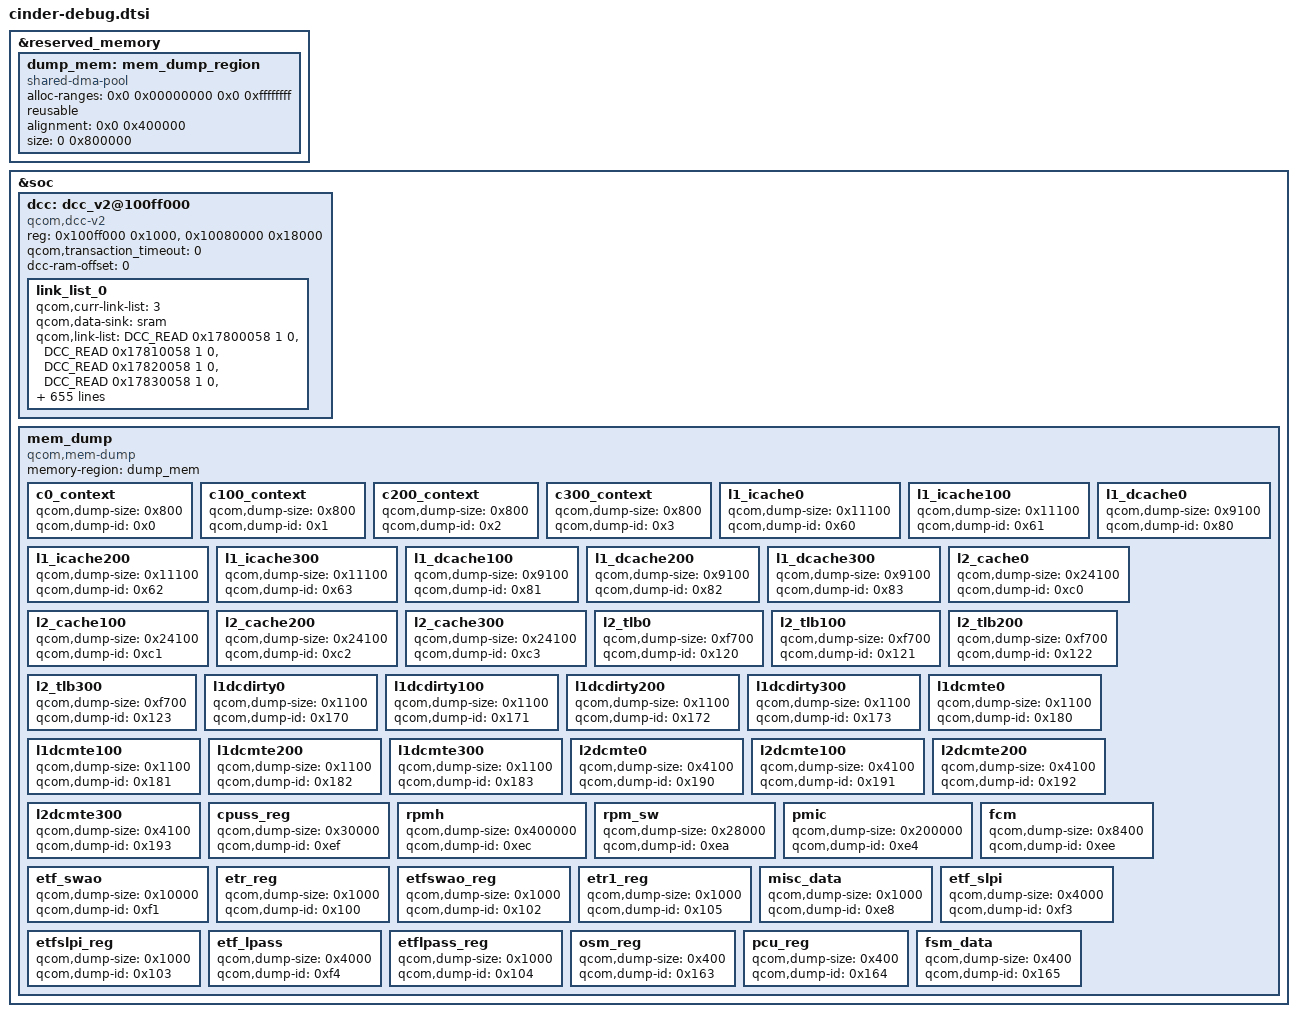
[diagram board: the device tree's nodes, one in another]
#include <dt-bindings/soc/qcom,dcc_v2.h>

&reserved_memory {
	#address-cells = <2>;
	#size-cells = <2>;
	ranges;

	dump_mem: mem_dump_region {
		compatible = "shared-dma-pool";
		alloc-ranges = <0x0 0x00000000 0x0 0xffffffff>;
		reusable;
		alignment = <0x0 0x400000>;
		size = <0 0x800000>;
	};
};

&soc {
	dcc: dcc_v2@100ff000 {
		compatible = "qcom,dcc-v2";
		reg = <0x100ff000 0x1000>,
		      <0x10080000 0x18000>;

		qcom,transaction_timeout = <0>;
		reg-names = "dcc-base", "dcc-ram-base";
		dcc-ram-offset = <0>;
		link_list_0 {
			qcom,curr-link-list = <3>;
			qcom,data-sink = "sram";
			qcom,link-list = <DCC_READ 0x17800058 1 0>,
					<DCC_READ 0x17810058 1 0>,
					<DCC_READ 0x17820058 1 0>,
					<DCC_READ 0x17830058 1 0>,
					<DCC_READ 0x1780005c 1 0>,
					<DCC_READ 0x1781005c 1 0>,
					<DCC_READ 0x1782005c 1 0>,
					<DCC_READ 0x1783005c 1 0>,
					<DCC_READ 0x1740003c 1 0>,
					<DCC_READ 0x17800060 1 0>,
					<DCC_READ 0x17810060 1 0>,
					<DCC_READ 0x17820060 1 0>,
					<DCC_READ 0x17830060 1 0>,
					<DCC_READ 0x17800064 1 0>,
					<DCC_READ 0x17810064 1 0>,
					<DCC_READ 0x17820064 1 0>,
					<DCC_READ 0x17830064 1 0>,
					<DCC_READ 0x17600238 1 0>,
					<DCC_READ 0x17600404 1 0>,
					<DCC_READ 0x1760041c 2 0>,
					<DCC_READ 0x17600434 1 0>,
					<DCC_READ 0x1760043c 2 0>,
					<DCC_WRITE 0x17a80000 0x8007 0>,
					<DCC_READ 0x17a80000 1 0>,
					<DCC_WRITE 0x17a80024 0x0 0>,
					<DCC_READ 0x17a80024 1 0>,
					<DCC_WRITE 0x17a80020 0x0 0>,
					<DCC_READ 0x17a80020 1 0>,
					<DCC_READ 0x17a80038 1 0>,
					<DCC_WRITE 0x17a80020 0x40 0>,
					<DCC_READ 0x17a80020 1 0>,
					<DCC_READ 0x17a80038 1 0>,
					<DCC_WRITE 0x17a80020 0x80 0>,
					<DCC_READ 0x17a80020 1 0>,
					<DCC_READ 0x17a80038 1 0>,
					<DCC_WRITE 0x17a80020 0xc0 0>,
					<DCC_READ 0x17a80020 1 0>,
					<DCC_READ 0x17a80038 1 0>,
					<DCC_WRITE 0x17a80020 0x100 0>,
					<DCC_READ 0x17a80020 1 0>,
					<DCC_READ 0x17a80038 1 0>,
					<DCC_WRITE 0x17a80020 0x140 0>,
					<DCC_READ 0x17a80020 1 0>,
					<DCC_READ 0x17a80038 1 0>,
					<DCC_WRITE 0x17a80020 0x180 0>,
					<DCC_READ 0x17a80020 1 0>,
					<DCC_READ 0x17a80038 1 0>,
					<DCC_WRITE 0x17a80020 0x1c0 0>,
					<DCC_READ 0x17a80020 1 0>,
					<DCC_READ 0x17a80038 1 0>,
					<DCC_WRITE 0x17a80020 0x200 0>,
					<DCC_READ 0x17a80020 1 0>,
					<DCC_READ 0x17a80038 1 0>,
					<DCC_WRITE 0x17a80020 0x240 0>,
					<DCC_READ 0x17a80020 1 0>,
					<DCC_READ 0x17a80038 1 0>,
					<DCC_WRITE 0x17a80020 0x280 0>,
					<DCC_READ 0x17a80020 1 0>,
					<DCC_READ 0x17a80038 1 0>,
					<DCC_WRITE 0x17a80020 0x2c0 0>,
					<DCC_READ 0x17a80020 1 0>,
					<DCC_READ 0x17a80038 1 0>,
					<DCC_WRITE 0x17a80020 0x300 0>,
					<DCC_READ 0x17a80020 1 0>,
					<DCC_READ 0x17a80038 1 0>,
					<DCC_WRITE 0x17a80020 0x340 0>,
					<DCC_READ 0x17a80020 1 0>,
					<DCC_READ 0x17a80038 1 0>,
					<DCC_WRITE 0x17a80020 0x380 0>,
					<DCC_READ 0x17a80020 1 0>,
					<DCC_READ 0x17a80038 1 0>,
					<DCC_WRITE 0x17a80020 0x3c0 0>,
					<DCC_READ 0x17a80020 1 0>,
					<DCC_READ 0x17a80038 1 0>,
					<DCC_WRITE 0x17a80020 0x4000 0>,
					<DCC_READ 0x17a80020 1 0>,
					<DCC_WRITE 0x17a80020 0x0 0>,
					<DCC_READ 0x17a80020 1 0>,
					<DCC_WRITE 0x17a80020 0x0 0>,
					<DCC_READ 0x17a80020 1 0>,
					<DCC_WRITE 0x17a80020 0x0 0>,
					<DCC_READ 0x17a80020 1 0>,
					<DCC_READ 0x17a80038 1 0>,
					<DCC_WRITE 0x17a80020 0x40 0>,
					<DCC_READ 0x17a80020 1 0>,
					<DCC_READ 0x17a80038 1 0>,
					<DCC_WRITE 0x17a84000 0x8007 0>,
					<DCC_READ 0x17a84000 1 0>,
					<DCC_WRITE 0x17a84024 0x0 0>,
					<DCC_READ 0x17a84024 1 0>,
					<DCC_WRITE 0x17a84020 0x0 0>,
					<DCC_READ 0x17a84020 1 0>,
					<DCC_READ 0x17a8400c 1 0>,
					<DCC_WRITE 0x17a84020 0x40 0>,
					<DCC_READ 0x17a84020 1 0>,
					<DCC_READ 0x17a8400c 1 0>,
					<DCC_WRITE 0x17a84020 0x80 0>,
					<DCC_READ 0x17a84020 1 0>,
					<DCC_READ 0x17a8400c 1 0>,
					<DCC_WRITE 0x17a84020 0xc0 0>,
					<DCC_READ 0x17a84020 1 0>,
					<DCC_READ 0x17a8400c 1 0>,
					<DCC_WRITE 0x17a84020 0x100 0>,
					<DCC_READ 0x17a84020 1 0>,
					<DCC_READ 0x17a8400c 1 0>,
					<DCC_WRITE 0x17a84020 0x140 0>,
					<DCC_READ 0x17a84020 1 0>,
					<DCC_READ 0x17a8400c 1 0>,
					<DCC_WRITE 0x17a84020 0x180 0>,
					<DCC_READ 0x17a84020 1 0>,
					<DCC_READ 0x17a8400c 1 0>,
					<DCC_WRITE 0x17a84020 0x1c0 0>,
					<DCC_READ 0x17a84020 1 0>,
					<DCC_READ 0x17a8400c 1 0>,
					<DCC_WRITE 0x17a84020 0x200 0>,
					<DCC_READ 0x17a84020 1 0>,
					<DCC_READ 0x17a8400c 1 0>,
					<DCC_WRITE 0x17a84020 0x240 0>,
					<DCC_READ 0x17a84020 1 0>,
					<DCC_READ 0x17a8400c 1 0>,
					<DCC_WRITE 0x17a84020 0x280 0>,
					<DCC_READ 0x17a84020 1 0>,
					<DCC_READ 0x17a8400c 1 0>,
					<DCC_WRITE 0x17a84020 0x2c0 0>,
					<DCC_READ 0x17a84020 1 0>,
					<DCC_READ 0x17a8400c 1 0>,
					<DCC_WRITE 0x17a84020 0x300 0>,
					<DCC_READ 0x17a84020 1 0>,
					<DCC_READ 0x17a8400c 1 0>,
					<DCC_WRITE 0x17a84020 0x340 0>,
					<DCC_READ 0x17a84020 1 0>,
					<DCC_READ 0x17a8400c 1 0>,
					<DCC_WRITE 0x17a84020 0x380 0>,
					<DCC_READ 0x17a84020 1 0>,
					<DCC_READ 0x17a8400c 1 0>,
					<DCC_WRITE 0x17a84020 0x3c0 0>,
					<DCC_READ 0x17a84020 1 0>,
					<DCC_READ 0x17a8400c 1 0>,
					<DCC_WRITE 0x17a84024 0x4000 0>,
					<DCC_READ 0x17a84024 1 0>,
					<DCC_WRITE 0x17a84020 0x0 0>,
					<DCC_READ 0x17a84020 1 0>,
					<DCC_WRITE 0x17a84020 0x0 0>,
					<DCC_READ 0x17a84020 1 0>,
					<DCC_WRITE 0x17a84020 0x0 0>,
					<DCC_READ 0x17a84020 1 0>,
					<DCC_READ 0x17a8400c 1 0>,
					<DCC_WRITE 0x17a84020 0x40 0>,
					<DCC_READ 0x17a84020 1 0>,
					<DCC_READ 0x17a8400c 1 0>,
					<DCC_READ 0xc201244 1 0>,
					<DCC_READ 0xc202244 1 0>,
					<DCC_READ 0x17b00000 70 0>,
					<DCC_READ 0x17B00000 1 0>,
					<DCC_READ 0x17800010 1 0>,
					<DCC_READ 0x17800024 1 0>,
					<DCC_READ 0x17800038 6 0>,
					<DCC_READ 0x1780006c 1 0>,
					<DCC_READ 0x178000f0 2 0>,
					<DCC_READ 0x17810010 1 0>,
					<DCC_READ 0x17810024 1 0>,
					<DCC_READ 0x17810038 6 0>,
					<DCC_READ 0x1781006c 1 0>,
					<DCC_READ 0x178100f0 2 0>,
					<DCC_READ 0x17820010 1 0>,
					<DCC_READ 0x17820024 1 0>,
					<DCC_READ 0x17820038 6 0>,
					<DCC_READ 0x1782006c 1 0>,
					<DCC_READ 0x178200f0 2 0>,
					<DCC_READ 0x17830010 1 0>,
					<DCC_READ 0x17830024 1 0>,
					<DCC_READ 0x17830038 6 0>,
					<DCC_READ 0x1783006c 1 0>,
					<DCC_READ 0x178300f0 2 0>,
					<DCC_READ 0x17880010 1 0>,
					<DCC_READ 0x17880024 1 0>,
					<DCC_READ 0x17880038 1 0>,
					<DCC_READ 0x17880040 1 0>,
					<DCC_READ 0x17880044 3 0>,
					<DCC_READ 0x1788006c 5 0>,
					<DCC_READ 0x17880084 1 0>,
					<DCC_READ 0x178800f4 5 0>,
					<DCC_READ 0x17880134 2 0>,
					<DCC_READ 0x178801b4 1 0>,
					<DCC_READ 0x178801bc 2 0>,
					<DCC_READ 0x178801c8 1 0>,
					<DCC_READ 0xb241024 1 0>,
					<DCC_READ 0xbde1034 1 0>,
					<DCC_READ 0xb201020 2 0>,
					<DCC_READ 0xb211020 2 0>,
					<DCC_READ 0xb221020 2 0>,
					<DCC_READ 0xb204520 1 0>,
					<DCC_READ 0xb200010 4 0>,
					<DCC_READ 0xb200900 4 0>,
					<DCC_READ 0xb201030 1 0>,
					<DCC_READ 0xb201204 2 0>,
					<DCC_READ 0xb201218 2 0>,
					<DCC_READ 0xb20122c 2 0>,
					<DCC_READ 0xb201240 2 0>,
					<DCC_READ 0xb201254 2 0>,
					<DCC_READ 0xb204510 2 0>,
					<DCC_READ 0xb220010 4 0>,
					<DCC_READ 0xb220900 4 0>,
					<DCC_READ 0x17a00010 1 0>,
					<DCC_READ 0x17a10010 1 0>,
					<DCC_READ 0x17a20010 1 0>,
					<DCC_READ 0x17a00030 1 0>,
					<DCC_READ 0x17a10030 1 0>,
					<DCC_READ 0x17a20030 1 0>,
					<DCC_READ 0x17a00038 1 0>,
					<DCC_READ 0x17a10038 1 0>,
					<DCC_READ 0x17a20038 1 0>,
					<DCC_READ 0x17a00040 1 0>,
					<DCC_READ 0x17a10040 1 0>,
					<DCC_READ 0x17a20040 1 0>,
					<DCC_READ 0x17a00048 1 0>,
					<DCC_READ 0x17a00400 3 0>,
					<DCC_READ 0x17a10400 3 0>,
					<DCC_READ 0x17a20400 3 0>,
					<DCC_READ 0x17d80100 144 0>,
					<DCC_READ 0x17d9001c 1 0>,
					<DCC_READ 0x17d900dc 1 0>,
					<DCC_READ 0x17d900e8 1 0>,
					<DCC_READ 0x17d90320 1 0>,
					<DCC_READ 0x17d90020 1 0>,
					<DCC_READ 0x17d9034c 1 0>,
					<DCC_READ 0x17d90300 1 0>,
					<DCC_READ 0x17d9101c 1 0>,
					<DCC_READ 0x17d910dc 1 0>,
					<DCC_READ 0x17d910e8 1 0>,
					<DCC_READ 0x17d91320 1 0>,
					<DCC_READ 0x17d91020 1 0>,
					<DCC_READ 0x17d9134c 1 0>,
					<DCC_READ 0x17d91300 1 0>,
					<DCC_READ 0x12822000 2 0>,
					<DCC_READ 0x12824c00 1 0>,
					<DCC_READ 0x12824d04 2 0>,
					<DCC_READ 0x17d98014 4 0>,
					<DCC_READ 0x17d900e0 1 0>,
					<DCC_READ 0x17d90410 1 0>,
					<DCC_READ 0x17d90074 1 0>,
					<DCC_READ 0x17d90064 1 0>,
					<DCC_READ 0x17d91074 1 0>,
					<DCC_READ 0x17d910e0 1 0>,
					<DCC_READ 0x17d91410 1 0>,
					<DCC_READ 0x17400038 1 0>,
					<DCC_READ 0x17d98010 1 0>,
					<DCC_READ 0x1fc8000 1 0>,
					<DCC_READ 0x17200104 29 0>,
					<DCC_READ 0x17200204 29 0>,
					<DCC_READ 0x17200384 29 0>,
					<DCC_READ 0x80000 2 0>,
					<DCC_READ 0x81000 2 0>,
					<DCC_READ 0x82000 2 0>,
					<DCC_READ 0x83000 2 0>,
					<DCC_READ 0x84000 2 0>,
					<DCC_READ 0x85000 2 0>,
					<DCC_READ 0x86000 2 0>,
					<DCC_READ 0x87000 2 0>,
					<DCC_READ 0x88000 2 0>,
					<DCC_READ 0xc2a0000 2 0>,
					<DCC_READ 0xc2a1000 2 0>,
					<DCC_READ 0xc2a900c 1 0>,
					<DCC_READ 0xa7168 1 0>,
					<DCC_READ 0xa729c 1 0>,
					<DCC_READ 0xa73d0 1 0>,
					<DCC_READ 0xa7504 1 0>,
					<DCC_READ 0xa7638 1 0>,
					<DCC_READ 0xa776c 1 0>,
					<DCC_READ 0xa8168 1 0>,
					<DCC_READ 0xa829c 1 0>,
					<DCC_READ 0xa83d0 1 0>,
					<DCC_READ 0xa8504 1 0>,
					<DCC_READ 0xa8638 1 0>,
					<DCC_READ 0xa876c 1 0>,
					<DCC_READ 0xd1028 1 0>,
					<DCC_READ 0x10406c 1 0>,
					<DCC_READ 0xa7034 1 0>,
					<DCC_READ 0xd4174 1 0>,
					<DCC_READ 0x113024 1 0>,
					<DCC_READ 0x10603c 1 0>,
					<DCC_READ 0x11d004 2 0>,
					<DCC_READ 0xfc004 2 0>,
					<DCC_READ 0xc9008 1 0>,
					<DCC_READ 0xc9004 1 0>,
					<DCC_READ 0xe2000 1 0>,
					<DCC_READ 0xe2008 1 0>,
					<DCC_READ 0xe2010 1 0>,
					<DCC_READ 0xe300c 1 0>,
					<DCC_READ 0xe3014 1 0>,
					<DCC_READ 0xe301c 1 0>,
					<DCC_READ 0xe6000 1 0>,
					<DCC_READ 0xe6008 1 0>,
					<DCC_READ 0xe6010 1 0>,
					<DCC_READ 0xe1000 1 0>,
					<DCC_READ 0xe1008 1 0>,
					<DCC_READ 0xe1010 1 0>,
					<DCC_READ 0xea000 1 0>,
					<DCC_READ 0xea008 1 0>,
					<DCC_READ 0xea010 1 0>,
					<DCC_READ 0xe7000 1 0>,
					<DCC_READ 0xe7008 1 0>,
					<DCC_READ 0xe7010 1 0>,
					<DCC_READ 0xf900c 1 0>,
					<DCC_READ 0xf9014 1 0>,
					<DCC_READ 0xf901c 1 0>,
					<DCC_READ 0xa0004 1 0>,
					<DCC_READ 0x120004 1 0>,
					<DCC_READ 0x113004 2 0>,
					<DCC_READ 0xd4004 1 0>,
					<DCC_READ 0x104008 2 0>,
					<DCC_READ 0x11d02c 1 0>,
					<DCC_READ 0x11d024 1 0>,
					<DCC_READ 0x11d048 1 0>,
					<DCC_READ 0x11d040 1 0>,
					<DCC_READ 0x11d01c 1 0>,
					<DCC_READ 0x11d018 1 0>,
					<DCC_READ 0xa1004 4 0>,
					<DCC_READ 0x150e8008 1 0>,
					<DCC_READ 0x150025dc 1 0>,
					<DCC_READ 0x150055dc 1 0>,
					<DCC_READ 0x150075dc 1 0>,
					<DCC_READ 0x150075dc 1 0>,
					<DCC_READ 0x15002204 1 0>,
					<DCC_READ 0x15002670 1 0>,
					<DCC_READ 0x15002648 1 0>,
					<DCC_READ 0x150022fc 3 0>,
					<DCC_READ 0x150022fc 1 0>,
					<DCC_READ 0x15002304 1 0>,
					<DCC_READ 0x19100010 1 0>,
					<DCC_READ 0x19100018 1 0>,
					<DCC_READ 0x19100020 1 0>,
					<DCC_READ 0x19100024 1 0>,
					<DCC_READ 0x19100028 1 0>,
					<DCC_READ 0x1910002C 1 0>,
					<DCC_READ 0x19100030 1 0>,
					<DCC_READ 0x19100034 1 0>,
					<DCC_READ 0x19100410 1 0>,
					<DCC_READ 0x19100418 1 0>,
					<DCC_READ 0x19100420 1 0>,
					<DCC_READ 0x19100424 1 0>,
					<DCC_READ 0x19100428 1 0>,
					<DCC_READ 0x1910042C 1 0>,
					<DCC_READ 0x19100430 1 0>,
					<DCC_READ 0x19100434 1 0>,
					<DCC_READ 0x19100810 1 0>,
					<DCC_READ 0x19100818 1 0>,
					<DCC_READ 0x19100820 1 0>,
					<DCC_READ 0x19100824 1 0>,
					<DCC_READ 0x19100828 1 0>,
					<DCC_READ 0x1910082C 1 0>,
					<DCC_READ 0x19100830 1 0>,
					<DCC_READ 0x19100834 1 0>,
					<DCC_READ 0x19100C10 1 0>,
					<DCC_READ 0x19100C18 1 0>,
					<DCC_READ 0x19100C20 1 0>,
					<DCC_READ 0x19100C24 1 0>,
					<DCC_READ 0x19100C28 1 0>,
					<DCC_READ 0x19100C2C 1 0>,
					<DCC_READ 0x19100C30 1 0>,
					<DCC_READ 0x19100C34 1 0>,
					<DCC_READ 0x19140010 1 0>,
					<DCC_READ 0x19140018 1 0>,
					<DCC_READ 0x19140020 1 0>,
					<DCC_READ 0x19140024 1 0>,
					<DCC_READ 0x19140028 1 0>,
					<DCC_READ 0x1914002C 1 0>,
					<DCC_READ 0x19140030 1 0>,
					<DCC_READ 0x19140034 1 0>,
					<DCC_READ 0x19140410 1 0>,
					<DCC_READ 0x19140418 1 0>,
					<DCC_READ 0x19140420 1 0>,
					<DCC_READ 0x19140424 1 0>,
					<DCC_READ 0x19140428 1 0>,
					<DCC_READ 0x1914042C 1 0>,
					<DCC_READ 0x19140430 1 0>,
					<DCC_READ 0x19140434 1 0>,
					<DCC_READ 0x19140810 1 0>,
					<DCC_READ 0x19140818 1 0>,
					<DCC_READ 0x19140820 1 0>,
					<DCC_READ 0x19140824 1 0>,
					<DCC_READ 0x19140828 1 0>,
					<DCC_READ 0x1914082C 1 0>,
					<DCC_READ 0x19140830 1 0>,
					<DCC_READ 0x19140834 1 0>,
					<DCC_READ 0x19140C10 1 0>,
					<DCC_READ 0x19140C18 1 0>,
					<DCC_READ 0x19140C20 1 0>,
					<DCC_READ 0x19140C24 1 0>,
					<DCC_READ 0x19140C28 1 0>,
					<DCC_READ 0x19140C2C 1 0>,
					<DCC_READ 0x19140C30 1 0>,
					<DCC_READ 0x19140C34 1 0>,
					<DCC_READ 0x19180010 1 0>,
					<DCC_READ 0x19180018 1 0>,
					<DCC_READ 0x19180020 1 0>,
					<DCC_READ 0x19180024 1 0>,
					<DCC_READ 0x19180028 1 0>,
					<DCC_READ 0x1918002C 1 0>,
					<DCC_READ 0x19180030 1 0>,
					<DCC_READ 0x19180034 1 0>,
					<DCC_READ 0x19180410 1 0>,
					<DCC_READ 0x19180418 1 0>,
					<DCC_READ 0x19180420 1 0>,
					<DCC_READ 0x19180424 1 0>,
					<DCC_READ 0x19180428 1 0>,
					<DCC_READ 0x1918042C 1 0>,
					<DCC_READ 0x19180430 1 0>,
					<DCC_READ 0x19180434 1 0>,
					<DCC_READ 0x19180810 1 0>,
					<DCC_READ 0x19180818 1 0>,
					<DCC_READ 0x19180820 1 0>,
					<DCC_READ 0x19180824 1 0>,
					<DCC_READ 0x19180828 1 0>,
					<DCC_READ 0x1918082C 1 0>,
					<DCC_READ 0x19180830 1 0>,
					<DCC_READ 0x19180834 1 0>,
					<DCC_READ 0x19104008 1 0>,
					<DCC_READ 0x1910400C 1 0>,
					<DCC_READ 0x19104408 1 0>,
					<DCC_READ 0x1910440C 1 0>,
					<DCC_READ 0x19104808 1 0>,
					<DCC_READ 0x1910480C 1 0>,
					<DCC_READ 0x19104C08 1 0>,
					<DCC_READ 0x19104C0C 1 0>,
					<DCC_READ 0x19144008 1 0>,
					<DCC_READ 0x1914400C 1 0>,
					<DCC_READ 0x19144408 1 0>,
					<DCC_READ 0x1914440C 1 0>,
					<DCC_READ 0x19144808 1 0>,
					<DCC_READ 0x1914480C 1 0>,
					<DCC_READ 0x19144C08 1 0>,
					<DCC_READ 0x19144C0C 1 0>,
					<DCC_READ 0x19184008 1 0>,
					<DCC_READ 0x1918400C 1 0>,
					<DCC_READ 0x19184408 1 0>,
					<DCC_READ 0x1918440C 1 0>,
					<DCC_READ 0x19184808 1 0>,
					<DCC_READ 0x1918480C 1 0>,
					<DCC_READ 0x19180C48 1 0>,
					<DCC_READ 0x19180C4C 1 0>,
					<DCC_READ 0x191AF010 1 0>,
					<DCC_READ 0x191B0010 1 0>,
					<DCC_READ 0x191B1010 1 0>,
					<DCC_READ 0x191B2010 1 0>,
					<DCC_READ 0x191B3010 1 0>,
					<DCC_READ 0x191B4010 1 0>,
					<DCC_READ 0x191B5010 1 0>,
					<DCC_READ 0x191B6010 1 0>,
					<DCC_READ 0x191B7010 1 0>,
					<DCC_READ 0x191B8010 1 0>,
					<DCC_READ 0x19102000 1 0>,
					<DCC_READ 0x19102004 1 0>,
					<DCC_LOOP 0x5 0 0>,
					<DCC_READ 0x19102008 1 0>,
					<DCC_READ 0x19102010 1 0>,
					<DCC_LOOP 0x1 0 0>,
					<DCC_READ 0x19102014 1 0>,
					<DCC_READ 0x19102018 1 0>,
					<DCC_READ 0x19102080 1 0>,
					<DCC_READ 0x19102084 1 0>,
					<DCC_READ 0x19102088 1 0>,
					<DCC_LOOP 0x5 0 0>,
					<DCC_READ 0x19102090 1 0>,
					<DCC_READ 0x19102094 1 0>,
					<DCC_LOOP 0x1 0 0>,
					<DCC_READ 0x19102098 1 0>,
					<DCC_READ 0x19142000 1 0>,
					<DCC_READ 0x19142004 1 0>,
					<DCC_READ 0x19142008 1 0>,
					<DCC_LOOP 0x5 0 0>,
					<DCC_READ 0x19142010 1 0>,
					<DCC_READ 0x19142014 1 0>,
					<DCC_LOOP 0x1 0 0>,
					<DCC_READ 0x19142018 1 0>,
					<DCC_READ 0x19142080 1 0>,
					<DCC_READ 0x19142084 1 0>,
					<DCC_READ 0x19142088 1 0>,
					<DCC_LOOP 0x5 0 0>,
					<DCC_READ 0x19142090 1 0>,
					<DCC_READ 0x19142094 1 0>,
					<DCC_LOOP 0x1 0 0>,
					<DCC_READ 0x19142098 1 0>,
					<DCC_READ 0x19182000 1 0>,
					<DCC_READ 0x19182004 1 0>,
					<DCC_READ 0x19182008 1 0>,
					<DCC_LOOP 0x4 0 0>,
					<DCC_READ 0x19182010 1 0>,
					<DCC_READ 0x19182014 1 0>,
					<DCC_LOOP 0x1 0 0>,
					<DCC_READ 0x19182018 1 0>,
					<DCC_READ 0x19182080 1 0>,
					<DCC_READ 0x19182084 1 0>,
					<DCC_READ 0x19182088 1 0>,
					<DCC_LOOP 0xb 0 0>,
					<DCC_READ 0x19182090 1 0>,
					<DCC_READ 0x19182094 1 0>,
					<DCC_LOOP 0x1 0 0>,
					<DCC_READ 0x19182098 1 0>,
					<DCC_READ 0x19104010 1 0>,
					<DCC_LOOP 0x40 0 0>,
					<DCC_READ 0x19104038 1 0>,
					<DCC_READ 0x19104030 2 0>,
					<DCC_READ 0x19104030 2 0>,
					<DCC_READ 0x19104030 2 0>,
					<DCC_READ 0x19104030 2 0>,
					<DCC_LOOP 0x1 0 0>,
					<DCC_READ 0x19104410 1 0>,
					<DCC_LOOP 0x40 0 0>,
					<DCC_READ 0x19104438 1 0>,
					<DCC_READ 0x19104430 2 0>,
					<DCC_READ 0x19104430 2 0>,
					<DCC_READ 0x19104430 2 0>,
					<DCC_READ 0x19104430 2 0>,
					<DCC_LOOP 0x1 0 0>,
					<DCC_READ 0x19104810 1 0>,
					<DCC_LOOP 0x40 0 0>,
					<DCC_READ 0x19104838 1 0>,
					<DCC_READ 0x19104830 2 0>,
					<DCC_READ 0x19104830 2 0>,
					<DCC_READ 0x19104830 2 0>,
					<DCC_READ 0x19104830 2 0>,
					<DCC_LOOP 0x1 0 0>,
					<DCC_READ 0x19104C10 1 0>,
					<DCC_LOOP 0x40 0 0>,
					<DCC_READ 0x19104C38 1 0>,
					<DCC_READ 0x19104C30 2 0>,
					<DCC_READ 0x19104C30 2 0>,
					<DCC_READ 0x19104C30 2 0>,
					<DCC_READ 0x19104C30 2 0>,
					<DCC_LOOP 0x1 0 0>,
					<DCC_READ 0x19144010 1 0>,
					<DCC_LOOP 0x40 0 0>,
					<DCC_READ 0x19144038 1 0>,
					<DCC_READ 0x19144030 2 0>,
					<DCC_READ 0x19144030 2 0>,
					<DCC_READ 0x19144030 2 0>,
					<DCC_READ 0x19144030 2 0>,
					<DCC_LOOP 0x1 0 0>,
					<DCC_READ 0x19144410 1 0>,
					<DCC_LOOP 0x40 0 0>,
					<DCC_READ 0x19144438 1 0>,
					<DCC_READ 0x19144430 2 0>,
					<DCC_READ 0x19144430 2 0>,
					<DCC_READ 0x19144430 2 0>,
					<DCC_READ 0x19144430 2 0>,
					<DCC_LOOP 0x1 0 0>,
					<DCC_READ 0x19144810 1 0>,
					<DCC_LOOP 0x40 0 0>,
					<DCC_READ 0x19144838 1 0>,
					<DCC_READ 0x19144830 2 0>,
					<DCC_READ 0x19144830 2 0>,
					<DCC_READ 0x19144830 2 0>,
					<DCC_READ 0x19144830 2 0>,
					<DCC_LOOP 0x1 0 0>,
					<DCC_READ 0x19144C10 1 0>,
					<DCC_LOOP 0x40 0 0>,
					<DCC_READ 0x19144C38 1 0>,
					<DCC_READ 0x19144C30 2 0>,
					<DCC_READ 0x19144C30 2 0>,
					<DCC_READ 0x19144C30 2 0>,
					<DCC_READ 0x19144C30 2 0>,
					<DCC_LOOP 0x1 0 0>,
					<DCC_READ 0x19184010 1 0>,
					<DCC_LOOP 0x40 0 0>,
					<DCC_READ 0x19184038 1 0>,
					<DCC_READ 0x19184030 2 0>,
					<DCC_READ 0x19184030 2 0>,
					<DCC_READ 0x19184030 2 0>,
					<DCC_READ 0x19184030 2 0>,
					<DCC_LOOP 0x1 0 0>,
					<DCC_READ 0x19184410 1 0>,
					<DCC_LOOP 0x40 0 0>,
					<DCC_READ 0x19184438 1 0>,
					<DCC_READ 0x19184430 2 0>,
					<DCC_READ 0x19184430 2 0>,
					<DCC_READ 0x19184430 2 0>,
					<DCC_READ 0x19184430 2 0>,
					<DCC_LOOP 0x1 0 0>,
					<DCC_READ 0x19184810 1 0>,
					<DCC_LOOP 0x40 0 0>,
					<DCC_READ 0x19184838 1 0>,
					<DCC_READ 0x19184830 2 0>,
					<DCC_READ 0x19184830 2 0>,
					<DCC_READ 0x19184830 2 0>,
					<DCC_READ 0x19184830 2 0>,
					<DCC_LOOP 0x1 0 0>,
					<DCC_READ 0x1640008 1 0>,
					<DCC_READ 0x1640010 1 0>,
					<DCC_READ 0x1640018 1 0>,
					<DCC_READ 0x1640020 1 0>,
					<DCC_READ 0x1640024 1 0>,
					<DCC_READ 0x1640028 1 0>,
					<DCC_READ 0x164002C 1 0>,
					<DCC_READ 0x1640030 1 0>,
					<DCC_READ 0x1640034 1 0>,
					<DCC_READ 0x1640038 1 0>,
					<DCC_READ 0x164003C 1 0>,
					<DCC_READ 0x1640240 1 0>,
					<DCC_READ 0x1640248 1 0>,
					<DCC_READ 0x1643040 1 0>,
					<DCC_READ 0x1643044 1 0>,
					<DCC_READ 0x1643048 1 0>,
					<DCC_READ 0x164304C 1 0>,
					<DCC_READ 0x1643050 1 0>,
					<DCC_READ 0x1643054 1 0>,
					<DCC_READ 0x1643058 1 0>,
					<DCC_READ 0x164305C 1 0>,
					<DCC_READ 0x1670010 1 0>,
					<DCC_READ 0x1674010 1 0>,
					<DCC_READ 0x1677010 1 0>,
					<DCC_READ 0x167A010 1 0>,
					<DCC_READ 0x167B010 1 0>,
					<DCC_READ 0x167C010 1 0>,
					<DCC_READ 0x167D010 1 0>,
					<DCC_READ 0x1680010 1 0>,
					<DCC_READ 0x1681010 1 0>,
					<DCC_READ 0x1682010 1 0>,
					<DCC_READ 0x1685010 1 0>,
					<DCC_READ 0x1641008 1 0>,
					<DCC_LOOP 0x6 0 0>,
					<DCC_READ 0x1641010 1 0>,
					<DCC_READ 0x1641014 1 0>,
					<DCC_LOOP 0x1 0 0>,
					<DCC_READ 0x1641018 1 0>,
					<DCC_READ 0x1641088 1 0>,
					<DCC_LOOP 0x6 0 0>,
					<DCC_READ 0x1641090 1 0>,
					<DCC_READ 0x1641094 1 0>,
					<DCC_LOOP 0x1 0 0>,
					<DCC_READ 0x1641098 1 0>,
					<DCC_READ 0x1641108 1 0>,
					<DCC_LOOP 0x16 0 0>,
					<DCC_READ 0x1641110 1 0>,
					<DCC_READ 0x1641114 1 0>,
					<DCC_LOOP 0x1 0 0>,
					<DCC_READ 0x1641118 1 0>,
					<DCC_LOOP 0x4 0 0>,
					<DCC_LOOP 0x1 0 0>,
					<DCC_READ 0x190E0008 1 0>,
					<DCC_READ 0x190E0010 1 0>,
					<DCC_READ 0x190E0018 1 0>,
					<DCC_READ 0x190E0020 1 0>,
					<DCC_READ 0x190E0024 1 0>,
					<DCC_READ 0x190E0028 1 0>,
					<DCC_READ 0x190E002C 1 0>,
					<DCC_READ 0x190E0030 1 0>,
					<DCC_READ 0x190E0034 1 0>,
					<DCC_READ 0x190E0038 1 0>,
					<DCC_READ 0x190E003C 1 0>,
					<DCC_READ 0x190E0240 1 0>,
					<DCC_READ 0x190E0248 1 0>,
					<DCC_READ 0x190E5008 1 0>,
					<DCC_LOOP 0x6 0 0>,
					<DCC_READ 0x190E5010 1 0>,
					<DCC_READ 0x190E5014 1 0>,
					<DCC_LOOP 0x1 0 0>,
					<DCC_READ 0x190E5018 1 0>,
					<DCC_READ 0x195F0008 1 0>,
					<DCC_READ 0x195F0010 1 0>,
					<DCC_READ 0x195F0018 1 0>,
					<DCC_READ 0x195F0020 1 0>,
					<DCC_READ 0x195F0024 1 0>,
					<DCC_READ 0x195F0028 1 0>,
					<DCC_READ 0x195F002C 1 0>,
					<DCC_READ 0x195F0030 1 0>,
					<DCC_READ 0x195F0034 1 0>,
					<DCC_READ 0x195F0038 1 0>,
					<DCC_READ 0x195F003C 1 0>,
					<DCC_READ 0x195F0240 1 0>,
					<DCC_READ 0x195F0248 1 0>,
					<DCC_READ 0x195F2008 1 0>,
					<DCC_LOOP 0x3 0 0>,
					<DCC_READ 0x195F2010 1 0>,
					<DCC_READ 0x195F2014 1 0>,
					<DCC_LOOP 0x1 0 0>,
					<DCC_READ 0x195F2018 1 0>,
					<DCC_READ 0x199F0008 1 0>,
					<DCC_READ 0x199F0010 1 0>,
					<DCC_READ 0x199F0018 1 0>,
					<DCC_READ 0x199F0020 1 0>,
					<DCC_READ 0x199F0024 1 0>,
					<DCC_READ 0x199F0028 1 0>,
					<DCC_READ 0x199F002C 1 0>,
					<DCC_READ 0x199F0030 1 0>,
					<DCC_READ 0x199F0034 1 0>,
					<DCC_READ 0x199F0038 1 0>,
					<DCC_READ 0x199F003C 1 0>,
					<DCC_READ 0x199F0240 1 0>,
					<DCC_READ 0x199F0248 1 0>,
					<DCC_READ 0x199F2008 1 0>,
					<DCC_LOOP 0x3 0 0>,
					<DCC_READ 0x199F2010 1 0>,
					<DCC_READ 0x199F2014 1 0>,
					<DCC_LOOP 0x1 0 0>,
					<DCC_READ 0x199F2018 1 0>,
					<DCC_READ 0x199F2008 1 0>,
					<DCC_READ 0x199F2010 1 0>,
					<DCC_READ 0x199F2014 1 0>,
					<DCC_READ 0x199F2018 1 0>,
					<DCC_READ 0x19DF0008 1 0>,
					<DCC_READ 0x19DF0010 1 0>,
					<DCC_READ 0x19DF0018 1 0>,
					<DCC_READ 0x19DF0020 1 0>,
					<DCC_READ 0x19DF0024 1 0>,
					<DCC_READ 0x19DF0028 1 0>,
					<DCC_READ 0x19DF002C 1 0>,
					<DCC_READ 0x19DF0030 1 0>,
					<DCC_READ 0x19DF0034 1 0>,
					<DCC_READ 0x19DF0038 1 0>,
					<DCC_READ 0x19DF003C 1 0>,
					<DCC_READ 0x19DF0240 1 0>,
					<DCC_READ 0x19DF0248 1 0>,
					<DCC_READ 0x19DF2008 1 0>,
					<DCC_LOOP 0x3 0 0>,
					<DCC_READ 0x19DF2010 1 0>,
					<DCC_READ 0x19DF2014 1 0>,
					<DCC_LOOP 0x1 0 0>,
					<DCC_READ 0x19DF2018 1 0>,
					<DCC_READ 0x1A1F0008 1 0>,
					<DCC_READ 0x1A1F0010 1 0>,
					<DCC_READ 0x1A1F0018 1 0>,
					<DCC_READ 0x1A1F0020 1 0>,
					<DCC_READ 0x1A1F0024 1 0>,
					<DCC_READ 0x1A1F0028 1 0>,
					<DCC_READ 0x1A1F002C 1 0>,
					<DCC_READ 0x1A1F0030 1 0>,
					<DCC_READ 0x1A1F0034 1 0>,
					<DCC_READ 0x1A1F0038 1 0>,
					<DCC_READ 0x1A1F003C 1 0>,
					<DCC_READ 0x1A1F0240 1 0>,
					<DCC_READ 0x1A1F0248 1 0>,
					<DCC_READ 0x1A1F2008 1 0>,
					<DCC_LOOP 0x3 0 0>,
					<DCC_READ 0x1A1F2010 1 0>,
					<DCC_READ 0x1A1F2014 1 0>,
					<DCC_LOOP 0x1 0 0>,
					<DCC_READ 0x1A1F2018 1 0>;
			};
	};

	mem_dump {
		compatible = "qcom,mem-dump";
		memory-region = <&dump_mem>;

		c0_context {
			qcom,dump-size = <0x800>;
			qcom,dump-id = <0x0>;
		};

		c100_context {
			qcom,dump-size = <0x800>;
			qcom,dump-id = <0x1>;
		};

		c200_context {
			qcom,dump-size = <0x800>;
			qcom,dump-id = <0x2>;
		};

		c300_context {
			qcom,dump-size = <0x800>;
			qcom,dump-id = <0x3>;
		};

		l1_icache0 {
			qcom,dump-size = <0x11100>;
			qcom,dump-id = <0x60>;
		};

		l1_icache100 {
			qcom,dump-size = <0x11100>;
			qcom,dump-id = <0x61>;
		};

		l1_icache200 {
			qcom,dump-size = <0x11100>;
			qcom,dump-id = <0x62>;
		};

		l1_icache300 {
			qcom,dump-size = <0x11100>;
			qcom,dump-id = <0x63>;
		};

		l1_dcache0 {
			qcom,dump-size = <0x9100>;
			qcom,dump-id = <0x80>;
		};

		l1_dcache100 {
			qcom,dump-size = <0x9100>;
			qcom,dump-id = <0x81>;
		};

		l1_dcache200 {
			qcom,dump-size = <0x9100>;
			qcom,dump-id = <0x82>;
		};

		l1_dcache300 {
			qcom,dump-size = <0x9100>;
			qcom,dump-id = <0x83>;
		};

		l2_cache0 {
			qcom,dump-size = <0x24100>;
			qcom,dump-id = <0xc0>;
		};

		l2_cache100 {
			qcom,dump-size = <0x24100>;
			qcom,dump-id = <0xc1>;
		};

		l2_cache200 {
			qcom,dump-size = <0x24100>;
			qcom,dump-id = <0xc2>;
		};

		l2_cache300 {
			qcom,dump-size = <0x24100>;
			qcom,dump-id = <0xc3>;
		};

		l2_tlb0 {
			qcom,dump-size = <0xf700>;
			qcom,dump-id = <0x120>;
		};

		l2_tlb100 {
			qcom,dump-size = <0xf700>;
			qcom,dump-id = <0x121>;
		};

		l2_tlb200 {
			qcom,dump-size = <0xf700>;
			qcom,dump-id = <0x122>;
		};

		l2_tlb300 {
			qcom,dump-size = <0xf700>;
			qcom,dump-id = <0x123>;
		};

		l1dcdirty0 {
			qcom,dump-size = <0x1100>;
			qcom,dump-id = <0x170>;
		};

		l1dcdirty100 {
			qcom,dump-size = <0x1100>;
			qcom,dump-id = <0x171>;
		};

		l1dcdirty200 {
			qcom,dump-size = <0x1100>;
			qcom,dump-id = <0x172>;
		};

		l1dcdirty300 {
			qcom,dump-size = <0x1100>;
			qcom,dump-id = <0x173>;
		};

		l1dcmte0 {
			qcom,dump-size = <0x1100>;
			qcom,dump-id = <0x180>;
		};

		l1dcmte100 {
			qcom,dump-size = <0x1100>;
			qcom,dump-id = <0x181>;
		};

		l1dcmte200 {
			qcom,dump-size = <0x1100>;
			qcom,dump-id = <0x182>;
		};

		l1dcmte300 {
			qcom,dump-size = <0x1100>;
			qcom,dump-id = <0x183>;
		};

		l2dcmte0 {
			qcom,dump-size = <0x4100>;
			qcom,dump-id = <0x190>;
		};

		l2dcmte100 {
			qcom,dump-size = <0x4100>;
			qcom,dump-id = <0x191>;
		};

		l2dcmte200 {
			qcom,dump-size = <0x4100>;
			qcom,dump-id = <0x192>;
		};

		l2dcmte300 {
			qcom,dump-size = <0x4100>;
			qcom,dump-id = <0x193>;
		};

		cpuss_reg {
			qcom,dump-size = <0x30000>;
			qcom,dump-id = <0xef>;
		};

		rpmh {
			qcom,dump-size = <0x400000>;
			qcom,dump-id = <0xec>;
		};

		rpm_sw {
			qcom,dump-size = <0x28000>;
			qcom,dump-id = <0xea>;
		};

		pmic {
			qcom,dump-size = <0x200000>;
			qcom,dump-id = <0xe4>;
		};

		fcm {
			qcom,dump-size = <0x8400>;
			qcom,dump-id = <0xee>;
		};

		etf_swao {
			qcom,dump-size = <0x10000>;
			qcom,dump-id = <0xf1>;
		};

		etr_reg {
			qcom,dump-size = <0x1000>;
			qcom,dump-id = <0x100>;
		};

		etfswao_reg {
			qcom,dump-size = <0x1000>;
			qcom,dump-id = <0x102>;
		};

		etr1_reg {
			qcom,dump-size = <0x1000>;
			qcom,dump-id = <0x105>;
		};

		misc_data {
			qcom,dump-size = <0x1000>;
			qcom,dump-id = <0xe8>;
		};

		etf_slpi {
			qcom,dump-size = <0x4000>;
			qcom,dump-id = <0xf3>;
		};

		etfslpi_reg {
			qcom,dump-size = <0x1000>;
			qcom,dump-id = <0x103>;
		};

		etf_lpass {
			qcom,dump-size = <0x4000>;
			qcom,dump-id = <0xf4>;
		};

		etflpass_reg {
			qcom,dump-size = <0x1000>;
			qcom,dump-id = <0x104>;
		};

		osm_reg {
			qcom,dump-size = <0x400>;
			qcom,dump-id = <0x163>;
		};

		pcu_reg {
			qcom,dump-size = <0x400>;
			qcom,dump-id = <0x164>;
		};

		fsm_data {
			qcom,dump-size = <0x400>;
			qcom,dump-id = <0x165>;
		};
	};
};
